# K32W061 register map
Vendor: nxp.com; File version: 1.0
CPU: CM4 r0p1, little endian, MPU, no FPU, VTOR, 3 interrupt priority bits
Registers are 32-bit, read-write, reset 0x0 unless marked. A register's access mark holds for its fields unless they carry their own. Offsets are from the block's base; [hi:lo] are bit positions; {n}, {i} and the like mark numbered series.

## PINT — This is the description of component pint It is a Pin Interrupt & Pattern matching module with APB bus interface. More details will follow.
Base 0x40010000
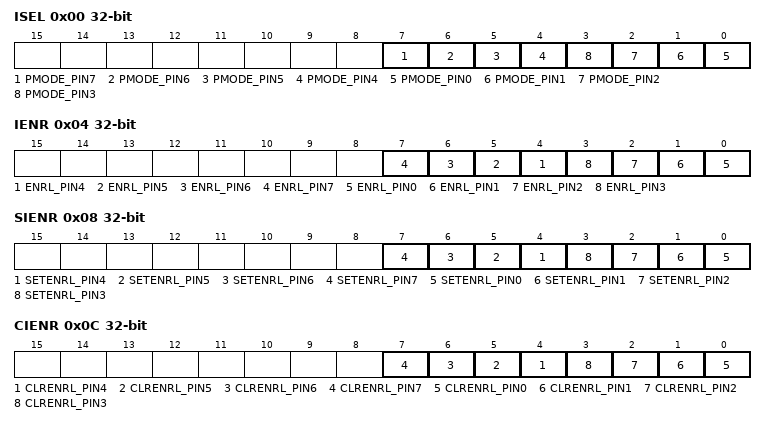
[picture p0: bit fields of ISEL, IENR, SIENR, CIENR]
0x00 ISEL — Pin Interrupt Mode register (only interrupts 0 to 3 supported to processor)
  [7] PMODE_PIN7 — Selects the interrupt mode for pin interrupt 7 (selected in PINTSEL7). [Note interrupt not supported to processor] 0: Edge sensitive. 1: Level sensitive.
  [6] PMODE_PIN6 — Selects the interrupt mode for pin interrupt 6 (selected in PINTSEL6). [Note interrupt not supported to processor] 0: Edge sensitive. 1: Level sensitive.
  [5] PMODE_PIN5 — Selects the interrupt mode for pin interrupt 5 (selected in PINTSEL5). [Note interrupt not supported to processor] 0: Edge sensitive 1: Level sensitive
  [4] PMODE_PIN4 — Selects the interrupt mode for pin interrupt 4 (selected in PINTSEL4). [Note interrupt not supported to processor] 0: Edge sensitive. 1: Level sensitive.
  [n] PMODE_PIN{n} (n=0..3) — Selects the interrupt mode for pin interrupt {n} (selected in PINTSEL{n}). 0: Edge sensitive. 1: Level sensitive.
0x04 IENR — Pin interrupt level or rising edge interrupt enable register (only interrupts 0 to 3 supported to processor)
  [n] ENRL_PIN{n} (n=4..7) — Enables the rising edge or level interrupt for pin interrupt {n} (selected in PINTSEL{n}). [Note interrupt not supported to processor] 0: Disable rising edge or level interrupt. 1: Enable rising edge or level interrupt.
  [n] ENRL_PIN{n} (n=0..3) — Enables the rising edge or level interrupt for pin interrupt {n} (selected in PINTSEL{n}). 0: Disable rising edge or level interrupt. 1: Enable rising edge or level interrupt.
0x08 SIENR reset not defined — Pin interrupt level or rising edge interrupt set register (only interrupts 0 to 3 supported to processor)
  [n] SETENRL_PIN{n} wo (n=4..7) — Ones written to this address set bits in the IENR, thus enabling interrupts. Bit {n} sets bit {n} in the IENR register. [Note interrupt not supported to processor] 0: No operation. 1: Enable rising edge or level interrupt.
  [n] SETENRL_PIN{n} wo (n=0..3) — Ones written to this address set bits in the IENR, thus enabling interrupts. Bit {n} sets bit {n} in the IENR register. 0: No operation. 1: Enable rising edge or level interrupt.
0x0C CIENR reset not defined — Pin interrupt level (rising edge interrupt) clear register (only interrupts 0 to 3 supported to processor)
  [n] CLRENRL_PIN{n} wo (n=4..7) — Ones written to this address clear bits in the IENR, thus disabling the interrupts. Bit {n} clears bit {n} in the IENR register. [Note interrupt not supported to processor] 0: No operation. 1: Disable rising edge or level interrupt.
  [n] CLRENRL_PIN{n} wo (n=0..3) — Ones written to this address clear bits in the IENR, thus disabling the interrupts. Bit {n} clears bit {n} in the IENR register. 0: No operation. 1: Disable rising edge or level interrupt.
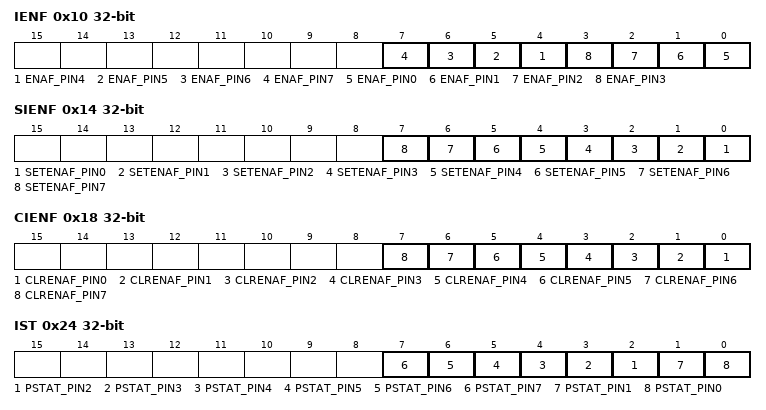
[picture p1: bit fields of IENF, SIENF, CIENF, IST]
0x10 IENF — Pin interrupt active level or falling edge interrupt enable register
  [n] ENAF_PIN{n} (n=4..7) — Enables the falling edge or configures the active level interrupt for pin interrupt {n} (selected in PINTSEL{n}). [Note interrupt not supported to processor] 0: Disable falling edge interrupt or set active interrupt level LOW. 1: Enable falling edge interrupt enabled or set active interrupt level HIGH.
  [n] ENAF_PIN{n} (n=0..3) — Enables the falling edge or configures the active level interrupt for pin interrupt {n} (selected in PINTSEL{n}). 0: Disable falling edge interrupt or set active interrupt level LOW. 1: Enable falling edge interrupt enabled or set active interrupt level HIGH.
0x14 SIENF reset not defined — Pin interrupt active level or falling edge interrupt set register
  [n] SETENAF_PIN{n} wo (n=0..7) — Ones written to this address set bits in the IENF, thus enabling interrupts. Bit {n} sets bit {n} in the IENF register. 0: No operation. 1: Select HIGH-active interrupt or enable falling edge interrupt.
0x18 CIENF reset not defined — Pin interrupt active level or falling edge interrupt clear register
  [n] CLRENAF_PIN{n} wo (n=0..7) — Ones written to this address clears bits in the IENF, thus disabling interrupts. Bit {n} clears bit {n} in the IENF register. 0: No operation. 1: LOW-active interrupt selected or falling edge interrupt disabled.
0x1C RISE — Pin interrupt rising edge register
  [7:0] RDET — Rising edge detect. Bit n detects the rising edge of the pin selected in PINTSELn. Read 0: No rising edge has been detected on this pin since Reset or the last time a one was written to this bit. Write 0: no operation. Read 1: a rising edge has been detected since Reset or the last time a one was written to this bit. Write 1: clear rising edge detection for this pin.
0x20 FALL — Pin interrupt falling edge register
  [7:0] FDET — Falling edge detect. Bit n detects the falling edge of the pin selected in PINTSELn. Read 0: No falling edge has been detected on this pin since Reset or the last time a one was written to this bit. Write 0: no operation. Read 1: a falling edge has been detected since Reset or the last time a one was written to this bit. Write 1: clear falling edge detection for this pin.
0x24 IST — Pin interrupt status register. For bits in this regsiter the following functionality occurs for the corresponding PIN bit: Read 0: interrupt is not being requested for this interrupt pin. Write 0: no operation. Read 1: interrupt is being requested for this interrupt pin. Write 1 (edge-sensitive): clear rising- and falling-edge detection for this pin. Write 1 (level-sensitive): switch the active level for this pin (in the IENF register).
  [n] PSTAT_PIN{n} (n=2..7) — Pin interrupt status. Bit {n} returns the status, clears the edge interrupt, or inverts the active level of the pin {n} (selected in PINTSEL{n}).
  [1] PSTAT_PIN1 — Pin interrupt status. Bit 1 returns the status, clears the edge interrupt, or inverts the active level of the pin 1 (selected in PINTSEL0).
  [0] PSTAT_PIN0 — Pin interrupt status. Bit 0 returns the status, clears the edge interrupt, or inverts the active level of the pin 0 (selected in PINTSEL0).
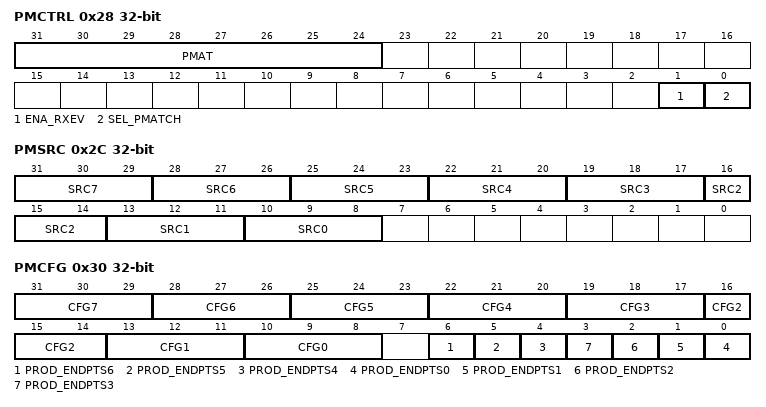
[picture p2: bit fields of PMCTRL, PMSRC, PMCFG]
0x28 PMCTRL — Pattern match interrupt control register
  [31:24] PMAT — This field displays the current state of pattern matches. A 1 in any bit of this field indicates that the corresponding product term is matched by the current state of the appropriate inputs.
  [1] ENA_RXEV — Enables the RXEV output to the CPU when the specified boolean expression evaluates to true. 0: Disabled. RXEV output to the CPU is disabled. 1: Enabled. RXEV output to the CPU is enabled.
  [0] SEL_PMATCH — Specifies whether the 8 pin interrupts are controlled by the pin interrupt function or by the pattern match function. 0: Pin interrupt. Interrupts are driven in response to the standard pin interrupt function. 1: Pattern match. Interrupts are driven in response to pattern matches.
0x2C PMSRC — Pattern match interrupt bit-slice source register
  [3n+10:3n+8] SRC{n} (n=0..7) — Selects the input source for bit slice {n}. Value X selects the pin selected in the PINTSELX register as the source to this bit slice. For example 3 selects the pin selected in PINTSEL3 regsiter.
0x30 PMCFG — Pattern match interrupt bit slice configuration register
  [3n+10:3n+8] CFG{n} (n=1..7) — Specifies the match contribution condition for bit slice {n}. See CFG0 for the modes available.
  [10:8] CFG0 — Specifies the match contribution condition for bit slice 0. 0x0: Constant HIGH. This bit slice always contributes to a product term match. 0x1: Sticky rising edge. Match occurs if a rising edge on the specified input has occurred since the last time the edge detection for this bit slice was cleared. This bit is only cleared when the PMCFG or the PMSRC registers are written to. 0x2: Sticky falling edge. Match occurs if a falling edge on the specified input has occurred since the last time the edge detection for this bit slice was cleared. This bit is only cleared when the PMCFG or the PMSRC registers are written to. 0x3: Sticky rising or falling edge. Match occurs if either a rising or falling edge on the specified input has occurred since the last time the edge detection for this bit slice was cleared. This bit is only cleared when the PMCFG or the PMSRC registers are written to. 0x4: High level. Match (for this bit slice) occurs when there is a high level on the input specified for this bit slice in the PMSRC register. 0x5: Low level. Match occurs when there is a low level on the specified input. 0x6: Constant 0. This bit slice never contributes to a match (should be used to disable any unused bit slices). 0x7: Event. Non-sticky rising or falling edge. Match occurs on an event - i.e. when either a rising or falling edge is first detected on the specified input (this is a non-sticky version of value 0x3). This bit is cleared after one clock cycle.
  [6] PROD_ENDPTS6 — Determines whether slice 6 is an endpoint. 0: No effect. Slice 6 is not an endpoint. 1: endpoint. Slice 6 is the endpoint of a product term (minterm). No NVIC interrupt is assocaited with this.
  [5] PROD_ENDPTS5 — Determines whether slice 5 is an endpoint. 0 No effect. Slice 5 is not an endpoint. 1: endpoint. Slice 5 is the endpoint of a product term (minterm). No NVIC interrupt is assocaited with this.
  [4] PROD_ENDPTS4 — Determines whether slice 4 is an endpoint. 0: No effect. Slice 4 is not an endpoint. 1: endpoint. Slice 4 is the endpoint of a product term (minterm). No NVIC interrupt is assocaited with this.
  [n] PROD_ENDPTS{n} (n=0..3) — Determines whether slice {n} is an endpoint. 0: No effect. Slice {n} is not an endpoint. 1: endpoint. Slice {n} is the endpoint of a product term (minterm). Interrupt PINT{n} in the NVIC is raised if the minterm evaluates as true.
